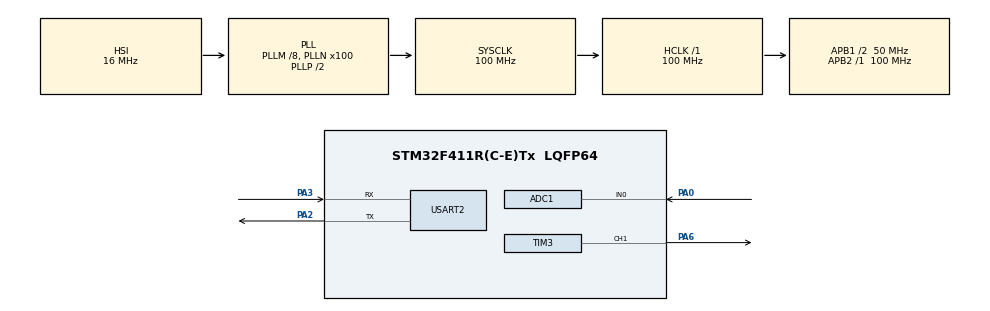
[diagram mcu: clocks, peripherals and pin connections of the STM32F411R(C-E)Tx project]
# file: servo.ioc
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ADC1.Channel-0\#ChannelRegularConversion=ADC_CHANNEL_0
ADC1.NbrOfConversionFlag=1
ADC1.Rank-0\#ChannelRegularConversion=1
ADC1.SamplingTime-0\#ChannelRegularConversion=ADC_SAMPLETIME_3CYCLES
ADC1.master=1
Mcu.Family=STM32F4
Mcu.Name=STM32F411R(C-E)Tx
Mcu.Package=LQFP64
NVIC.PriorityGroup=NVIC_PRIORITYGROUP_4
NVIC.USART2_IRQn=true\:0\:0\:false\:false\:true\:true\:true\:true
PA0-WKUP.Signal=ADCx_IN0
PA2.Mode=Asynchronous
PA2.Signal=USART2_TX
PA3.Mode=Asynchronous
PA3.Signal=USART2_RX
PA6.Signal=S_TIM3_CH1
ProjectManager.HeapSize=0x200
ProjectManager.StackSize=0x400
ProjectManager.TargetToolchain=STM32CubeIDE
RCC.48MHZClocksFreq_Value=50000000
RCC.AHBFreq_Value=100000000
RCC.APB1CLKDivider=RCC_HCLK_DIV2
RCC.APB1Freq_Value=50000000
RCC.APB1TimFreq_Value=100000000
RCC.APB2Freq_Value=100000000
RCC.APB2TimFreq_Value=100000000
RCC.CortexFreq_Value=100000000
RCC.HCLKFreq_Value=100000000
RCC.HSE_VALUE=25000000
RCC.HSI_VALUE=16000000
RCC.LSE_VALUE=32768
RCC.PLLM=8
RCC.PLLN=100
RCC.SYSCLKFreq_VALUE=100000000
RCC.SYSCLKSource=RCC_SYSCLKSOURCE_PLLCLK
RCC.VCOOutputFreq_Value=200000000
SH.ADCx_IN0.0=ADC1_IN0,IN0
SH.S_TIM3_CH1.0=TIM3_CH1,PWM Generation1 CH1
TIM3.Channel-PWM\ Generation1\ CH1=TIM_CHANNEL_1
TIM3.Period=20000-1
TIM3.Prescaler=100-1
TIM3.Pulse-PWM\ Generation1\ CH1=1500-1
USART2.VirtualMode=VM_ASYNC
VP_TIM3_VS_ClockSourceINT.Mode=Internal
board=custom

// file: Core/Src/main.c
/* USER CODE BEGIN Header */
/**
  ******************************************************************************
  * @file           : main.c
  * @brief          : Main program body
  ******************************************************************************
  * @attention
  *
  * Copyright (c) 2024 STMicroelectronics.
  * All rights reserved.
  *
  * This software is licensed under terms that can be found in the LICENSE file
  * in the root directory of this software component.
  * If no LICENSE file comes with this software, it is provided AS-IS.
  *
  ******************************************************************************
  */
/* USER CODE END Header */
#include "main.h"

/* USER CODE BEGIN Includes */
#include "uart.h"
/* USER CODE END Includes */

ADC_HandleTypeDef hadc1;

TIM_HandleTypeDef htim3;

UART_HandleTypeDef huart2;

void SystemClock_Config(void);
static void MX_GPIO_Init(void);
static void MX_TIM3_Init(void);
static void MX_ADC1_Init(void);
static void MX_USART2_UART_Init(void);

/* USER CODE BEGIN 0 */
//range setting
long map(long x, long in_min, long in_max, long out_min, long out_max) {
  return (x - in_min) * (out_max - out_min) / (in_max - in_min) + out_min;
}
/* USER CODE END 0 */

int main(void)
{

  /* MCU Configuration--------------------------------------------------------*/

  /* Reset of all peripherals, Initializes the Flash interface and the Systick. */
  HAL_Init();

  /* Configure the system clock */
  SystemClock_Config();

  /* Initialize all configured peripherals */
  MX_GPIO_Init();
  MX_TIM3_Init();
  MX_ADC1_Init();
  MX_USART2_UART_Init();
  /* USER CODE BEGIN 2 */
  HAL_TIM_PWM_Start(&htim3, TIM_CHANNEL_1);
  initUart(&huart2);
  /* USER CODE END 2 */

  /* Infinite loop */
  /* USER CODE BEGIN WHILE */
  while (1)
  {
  	//ADC conversion start
  	HAL_ADC_Start(&hadc1);
  	//Finish to standby
  	HAL_ADC_PollForConversion(&hadc1, 10);
  	//read value
  	uint16_t result = HAL_ADC_GetValue(&hadc1);
  	//Finish
  	HAL_ADC_Stop(&hadc1);
  	uint16_t servoValue = map(result, 0, 4095, 600, 2400);
  	htim3.Instance->CCR1 = servoValue;
  	printf("%d\n", servoValue);
  	HAL_Delay(10);
  	//

    /* USER CODE END WHILE */

  }
}

void SystemClock_Config(void)
{
  RCC_OscInitTypeDef RCC_OscInitStruct = {0};
  RCC_ClkInitTypeDef RCC_ClkInitStruct = {0};

  /** Configure the main internal regulator output voltage
  */
  __HAL_RCC_PWR_CLK_ENABLE();
  __HAL_PWR_VOLTAGESCALING_CONFIG(PWR_REGULATOR_VOLTAGE_SCALE1);

  /** Initializes the RCC Oscillators according to the specified parameters
  * in the RCC_OscInitTypeDef structure.
  */
  RCC_OscInitStruct.OscillatorType = RCC_OSCILLATORTYPE_HSI;
  RCC_OscInitStruct.HSIState = RCC_HSI_ON;
  RCC_OscInitStruct.HSICalibrationValue = RCC_HSICALIBRATION_DEFAULT;
  RCC_OscInitStruct.PLL.PLLState = RCC_PLL_ON;
  RCC_OscInitStruct.PLL.PLLSource = RCC_PLLSOURCE_HSI;
  RCC_OscInitStruct.PLL.PLLM = 8;
  RCC_OscInitStruct.PLL.PLLN = 100;
  RCC_OscInitStruct.PLL.PLLP = RCC_PLLP_DIV2;
  RCC_OscInitStruct.PLL.PLLQ = 4;
  if (HAL_RCC_OscConfig(&RCC_OscInitStruct) != HAL_OK)
  {
    Error_Handler();
  }

  /** Initializes the CPU, AHB and APB buses clocks
  */
  RCC_ClkInitStruct.ClockType = RCC_CLOCKTYPE_HCLK|RCC_CLOCKTYPE_SYSCLK
                              |RCC_CLOCKTYPE_PCLK1|RCC_CLOCKTYPE_PCLK2;
  RCC_ClkInitStruct.SYSCLKSource = RCC_SYSCLKSOURCE_PLLCLK;
  RCC_ClkInitStruct.AHBCLKDivider = RCC_SYSCLK_DIV1;
  RCC_ClkInitStruct.APB1CLKDivider = RCC_HCLK_DIV2;
  RCC_ClkInitStruct.APB2CLKDivider = RCC_HCLK_DIV1;

  if (HAL_RCC_ClockConfig(&RCC_ClkInitStruct, FLASH_LATENCY_3) != HAL_OK)
  {
    Error_Handler();
  }
}

static void MX_ADC1_Init(void)
{

  ADC_ChannelConfTypeDef sConfig = {0};

  /** Configure the global features of the ADC (Clock, Resolution, Data Alignment and number of conversion)
  */
  hadc1.Instance = ADC1;
  hadc1.Init.ClockPrescaler = ADC_CLOCK_SYNC_PCLK_DIV4;
  hadc1.Init.Resolution = ADC_RESOLUTION_12B;
  hadc1.Init.ScanConvMode = DISABLE;
  hadc1.Init.ContinuousConvMode = DISABLE;
  hadc1.Init.DiscontinuousConvMode = DISABLE;
  hadc1.Init.ExternalTrigConvEdge = ADC_EXTERNALTRIGCONVEDGE_NONE;
  hadc1.Init.ExternalTrigConv = ADC_SOFTWARE_START;
  hadc1.Init.DataAlign = ADC_DATAALIGN_RIGHT;
  hadc1.Init.NbrOfConversion = 1;
  hadc1.Init.DMAContinuousRequests = DISABLE;
  hadc1.Init.EOCSelection = ADC_EOC_SINGLE_CONV;
  if (HAL_ADC_Init(&hadc1) != HAL_OK)
  {
    Error_Handler();
  }

  /** Configure for the selected ADC regular channel its corresponding rank in the sequencer and its sample time.
  */
  sConfig.Channel = ADC_CHANNEL_0;
  sConfig.Rank = 1;
  sConfig.SamplingTime = ADC_SAMPLETIME_3CYCLES;
  if (HAL_ADC_ConfigChannel(&hadc1, &sConfig) != HAL_OK)
  {
    Error_Handler();
  }

}

static void MX_TIM3_Init(void)
{

  TIM_ClockConfigTypeDef sClockSourceConfig = {0};
  TIM_MasterConfigTypeDef sMasterConfig = {0};
  TIM_OC_InitTypeDef sConfigOC = {0};

  htim3.Instance = TIM3;
  htim3.Init.Prescaler = 100-1;
  htim3.Init.CounterMode = TIM_COUNTERMODE_UP;
  htim3.Init.Period = 20000-1;
  htim3.Init.ClockDivision = TIM_CLOCKDIVISION_DIV1;
  htim3.Init.AutoReloadPreload = TIM_AUTORELOAD_PRELOAD_DISABLE;
  if (HAL_TIM_Base_Init(&htim3) != HAL_OK)
  {
    Error_Handler();
  }
  sClockSourceConfig.ClockSource = TIM_CLOCKSOURCE_INTERNAL;
  if (HAL_TIM_ConfigClockSource(&htim3, &sClockSourceConfig) != HAL_OK)
  {
    Error_Handler();
  }
  if (HAL_TIM_PWM_Init(&htim3) != HAL_OK)
  {
    Error_Handler();
  }
  sMasterConfig.MasterOutputTrigger = TIM_TRGO_RESET;
  sMasterConfig.MasterSlaveMode = TIM_MASTERSLAVEMODE_DISABLE;
  if (HAL_TIMEx_MasterConfigSynchronization(&htim3, &sMasterConfig) != HAL_OK)
  {
    Error_Handler();
  }
  sConfigOC.OCMode = TIM_OCMODE_PWM1;
  sConfigOC.Pulse = 1500-1;
  sConfigOC.OCPolarity = TIM_OCPOLARITY_HIGH;
  sConfigOC.OCFastMode = TIM_OCFAST_DISABLE;
  if (HAL_TIM_PWM_ConfigChannel(&htim3, &sConfigOC, TIM_CHANNEL_1) != HAL_OK)
  {
    Error_Handler();
  }
  HAL_TIM_MspPostInit(&htim3);

}

static void MX_USART2_UART_Init(void)
{

  huart2.Instance = USART2;
  huart2.Init.BaudRate = 115200;
  huart2.Init.WordLength = UART_WORDLENGTH_8B;
  huart2.Init.StopBits = UART_STOPBITS_1;
  huart2.Init.Parity = UART_PARITY_NONE;
  huart2.Init.Mode = UART_MODE_TX_RX;
  huart2.Init.HwFlowCtl = UART_HWCONTROL_NONE;
  huart2.Init.OverSampling = UART_OVERSAMPLING_16;
  if (HAL_UART_Init(&huart2) != HAL_OK)
  {
    Error_Handler();
  }

}

static void MX_GPIO_Init(void)
{

  /* GPIO Ports Clock Enable */
  __HAL_RCC_GPIOA_CLK_ENABLE();

}

void Error_Handler(void)
{
  __disable_irq();
  while (1)
  {
  }
}
